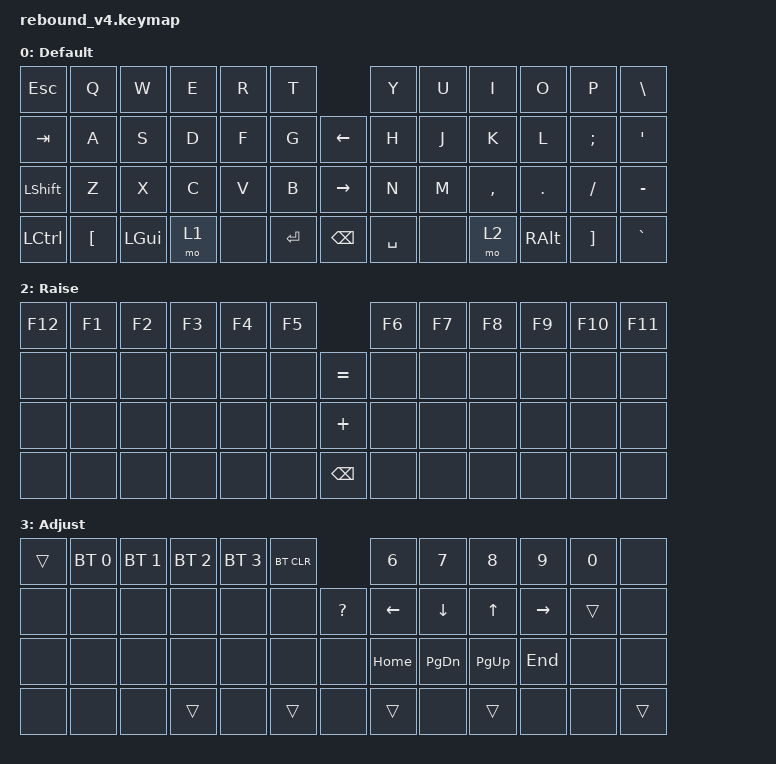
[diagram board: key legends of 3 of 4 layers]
/*
 * Copyright (c) 2020 The ZMK Contributors
 *
 * SPDX-License-Identifier: MIT
 */

#include <behaviors.dtsi>
#include <dt-bindings/zmk/keys.h>
#include <dt-bindings/zmk/bt.h>
#include <dt-bindings/zmk/outputs.h>
#include <dt-bindings/zmk/ext_power.h>
#include <dt-bindings/zmk/rgb.h>

#define DEFAULT 0
#define LWR     1
#define RAS     2
#define ADJ     3

&caps_word {
    continue-list = <UNDERSCORE MINUS>;
};

/ {
    combos {
    };
  };

/ {
    conditional_layers {
        compatible = "zmk,conditional-layers";
        tri_layer {
            if-layers = <1 2>;
            then-layer = <3>;
        };
    };
};

/ {

    behaviors {
        hm: homerow_mods {
            compatible = "zmk,behavior-hold-tap";
            label = "HOMEROW_MODS";
            #binding-cells = <2>;
            tapping-term-ms = <200>;
            quick_tap_ms = <0>;
            flavor = "tap-preferred";
            bindings = <&kp>, <&kp>;
        };
        hs: homerow_shift {
            compatible = "zmk,behavior-hold-tap";
            label = "HOMEROW_MODS";
            #binding-cells = <2>;
            tapping-term-ms = <250>;
            quick_tap_ms = <0>;
            flavor = "tap-preferred";
            bindings = <&kp>, <&kp>;
        };
        am: amethyst_modifyers {
            compatible = "zmk,behavior-hold-tap";
            label = "AMETHYST_MODIFYER";
            #binding-cells = <2>;
            tapping-term-ms = <250>;
            quick_tap_ms = <0>;
            flavor = "tap-preferred";
            bindings = <&kp>, <&kp>;
        };
    };

        keymap {
        compatible = "zmk,keymap";

        default_layer {        
            label = "Default";              					  
		    bindings = <
                &kp ESC     &kp Q       &kp W       &kp E       &kp R    &kp T                          &kp Y       &kp U    &kp I      &kp O       &kp P       &kp BSLH
                &kp TAB     &kp A       &kp S       &kp D       &kp F    &kp G      &kp LEFT            &kp H       &kp J    &kp K      &kp L       &kp SEMI    &kp SQT
                &kp LSHFT   &kp Z       &kp X       &kp C       &kp V    &kp B      &kp RIGHT           &kp N       &kp M    &kp COMMA  &kp DOT     &kp FSLH    &kp MINUS
                &kp LCTRL   &kp LBKT    &kp LGUI    &mo 1       &none    &kp RET    &kp BSPC            &kp SPACE   &none    &mo 2      &kp RALT    &kp RBKT    &kp GRAVE                
                        >;
			            sensor-bindings = <&inc_dec_kp LG(LS(RBKT)) LG(LS(LBKT))>;
                };

        lower_layer {        
            label = "Lower";              					  
		    bindings = <
                &kp TILDE   &kp N1      &kp N2      &kp N3      &kp N4   &kp N5                         &kp N6      &kp N7   &kp N8    &kp N9  &kp N0   &kp PG_UP
                &kp GRAVE   &none       &kp UP      &none       &none    &none      &kp EQUAL           &none       &none    &none     &none   &none    &kp PG_DN
                &none       &kp LEFT    &kp DOWN    &kp RIGHT   &kp N4   &kp N5     &kp PLUS            &none       &none    &none     &none   &none    &none
                &none       &none       &none       &mo 1       &none               &kp BSPC                        &none    &mo 2     &none   &none    &none
                        >;
                        sensor-bindings = <&inc_dec_kp C_VOLUME_UP C_VOLUME_DOWN>;
                };
        raise_layer {        
            label = "Raise";              					  
		    bindings = <
                &kp F12     &kp F1      &kp F2      &kp F3      &kp F4    &kp F5                  &kp F6      &kp F7   &kp F8   &kp F9   &kp F10   &kp F11 
                &none       &none       &none       &none      &none      &none       &kp EQUAL   &none      &none   &none   &none   &none   &none 
                &none       &none       &none       &none      &none      &none       &kp PLUS    &none      &none   &none   &none   &none   &none
                &none       &none       &none       &none      &none      &none       &kp BSPC    &none      &none   &none   &none   &none   &none
                        >;
			            sensor-bindings = <&inc_dec_kp LG(LS(RBKT)) LG(LS(LBKT))>;
                };
        adjust_layer {        
            label = "Adjust";              					  
		    bindings = <
        &trans              &bt BT_SEL 0 &bt BT_SEL 1 &bt BT_SEL 2 &bt BT_SEL 3    &bt BT_CLR                                      &kp N6                  &kp N7        &kp N8        &kp N9      &kp N0          &none 
        &none               &none        &none        &none        &none           &none                    &kp QMARK              &kp LEFT                &kp DOWN      &kp UP        &kp RIGHT   &trans          &none 
        &none               &none        &none        &none        &none           &none                    &none                  &kp HOME                &kp PG_DN     &kp PG_UP     &kp END     &none           &none 
        &none               &none        &none        &trans       &none           &trans                   &none                  &trans                  &none         &trans        &none       &none           &trans
                        >;
			            sensor-bindings = <&inc_dec_kp LG(LS(LBKT)) LG(LS(RBKT))>;
                };       
        };
};
